# STM32L151xD register map
File version: 1.0
Registers are 32-bit, read-write, reset 0x0 unless marked. A register's access mark holds for its fields unless they carry their own. Offsets are from the block's base; [hi:lo] are bit positions; {n}, {i} and the like mark numbered series; 'fields as' and 'values as' point back to an identical list.

## FSMC_Bank1 — Flexible Static Memory Controller
Base 0xA0000000
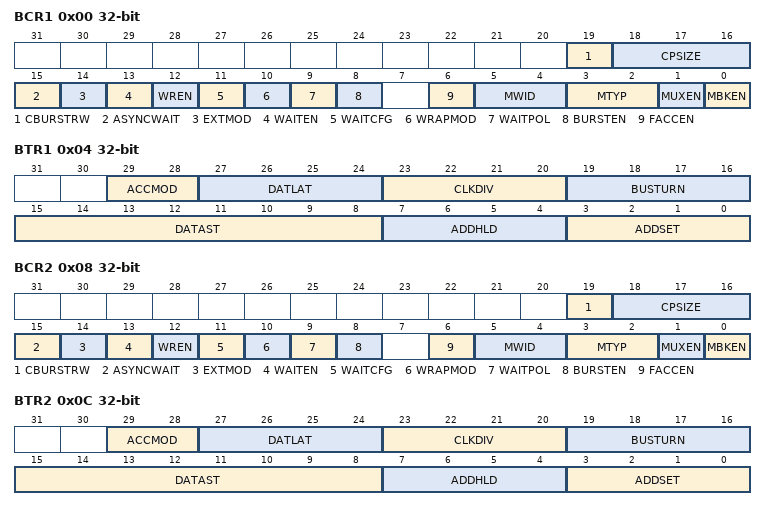
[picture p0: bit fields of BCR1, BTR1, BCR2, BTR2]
0x00 BCR1 — NOR/PSRAM chip-select control register(BCR) and chip-select timing register(BTR)
  [19] CBURSTRW — Write burst enable
  [18:16] CPSIZE — Cellular RAM page size
  [15] ASYNCWAIT — Asynchronous wait
  [14] EXTMOD — Extended mode enable
  [13] WAITEN — Wait enable bit
  [12] WREN — Write enable bit
  [11] WAITCFG — Wait timing configuration
  [10] WRAPMOD — Wrapped burst mode support
  [9] WAITPOL — Wait signal polarity bit
  [8] BURSTEN — Burst enable bit
  [6] FACCEN — Flash access enable
  [5:4] MWID — MWID[1:0] bits (Memory data bus width)
  [3:2] MTYP — MTYP[1:0] bits (Memory type)
  [1] MUXEN — Address/data multiplexing enable bit
  [0] MBKEN — Memory bank enable bit
0x04 BTR1 — NOR/PSRAM chip-select control register(BCR) and chip-select timing register(BTR)
  [29:28] ACCMOD — ACCMOD[1:0] bits (Access mode)
  [27:24] DATLAT — DATLA[3:0] bits (Data latency)
  [23:20] CLKDIV — CLKDIV[3:0] bits (Clock divide ratio)
  [19:16] BUSTURN — BUSTURN[3:0] bits (Bus turnaround phase duration)
  [15:8] DATAST — DATAST [7:0] bits (Data-phase duration)
  [7:4] ADDHLD — ADDHLD[3:0] bits (Address-hold phase duration)
  [3:0] ADDSET — ADDSET[3:0] bits (Address setup phase duration)
0x08 BCR2 — NOR/PSRAM chip-select control register(BCR) and chip-select timing register(BTR)
  fields as BCR1
0x0C BTR2 — NOR/PSRAM chip-select control register(BCR) and chip-select timing register(BTR)
  fields as BTR1
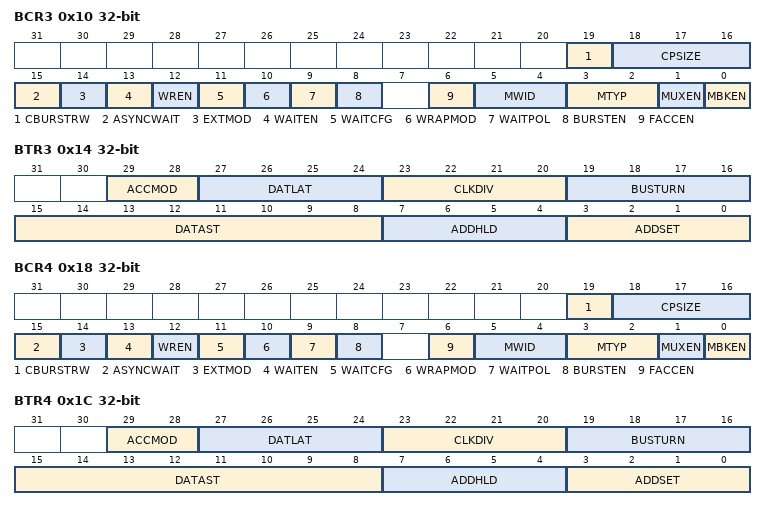
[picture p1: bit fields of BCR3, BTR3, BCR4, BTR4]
0x10 BCR3 — NOR/PSRAM chip-select control register(BCR) and chip-select timing register(BTR)
  fields as BCR1
0x14 BTR3 — NOR/PSRAM chip-select control register(BCR) and chip-select timing register(BTR)
  fields as BTR1
0x18 BCR4 — NOR/PSRAM chip-select control register(BCR) and chip-select timing register(BTR)
  fields as BCR1
0x1C BTR4 — NOR/PSRAM chip-select control register(BCR) and chip-select timing register(BTR)
  fields as BTR1

## FSMC_Bank1E — Flexible Static Memory Controller Bank1E
Base 0xA0000104
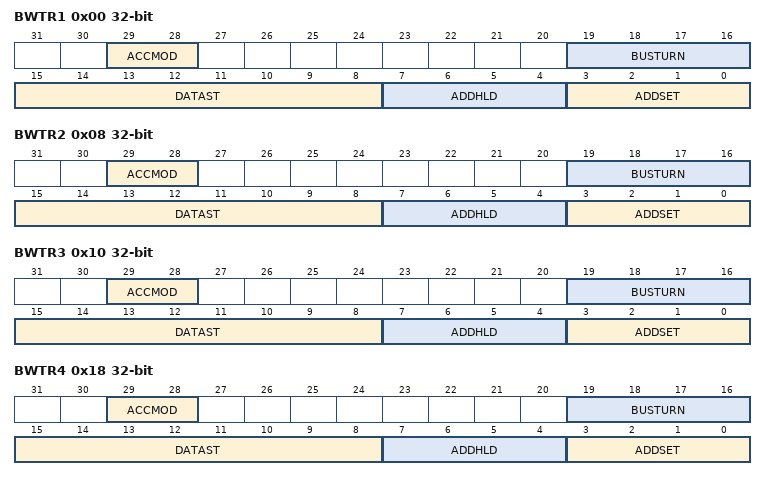
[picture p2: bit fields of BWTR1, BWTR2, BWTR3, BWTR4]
0x00 BWTR1 — NOR/PSRAM write timing registers
  [29:28] ACCMOD — ACCMOD[1:0] bits (Access mode)
  [19:16] BUSTURN — BUSTURN[3:0] bits (Bus turnaround phase duration)
  [15:8] DATAST — DATAST [7:0] bits (Data-phase duration)
  [7:4] ADDHLD — ADDHLD[3:0] bits (Address-hold phase duration)
  [3:0] ADDSET — ADDSET[3:0] bits (Address setup phase duration)
0x08 BWTR2 — NOR/PSRAM write timing registers
  fields as BWTR1
0x10 BWTR3 — NOR/PSRAM write timing registers
  fields as BWTR1
0x18 BWTR4 — NOR/PSRAM write timing registers
  fields as BWTR1

## DBGMCU — Debug MCU
Base 0xE0042000
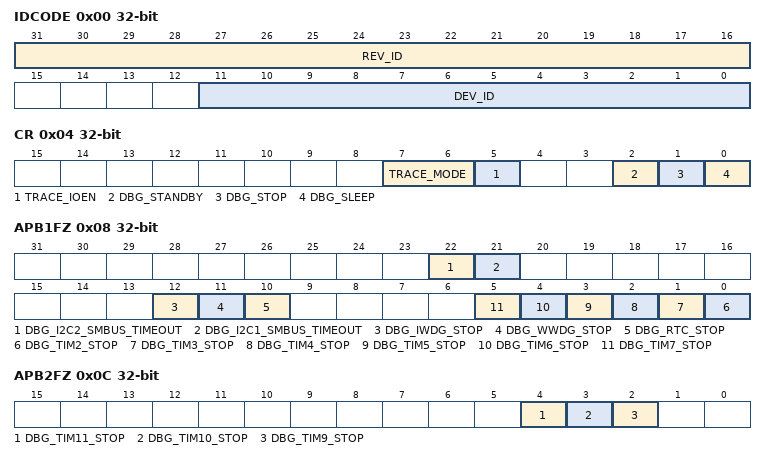
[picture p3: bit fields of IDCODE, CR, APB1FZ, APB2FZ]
0x00 IDCODE — MCU device ID code
  [31:16] REV_ID — REV_ID[15:0] bits (Revision Identifier)
  [11:0] DEV_ID — Device Identifier
0x04 CR — Debug MCU configuration register
  [7:6] TRACE_MODE — TRACE_MODE[1:0] bits (Trace Pin Assignment Control)
  [5] TRACE_IOEN — Trace Pin Assignment Control
  [2] DBG_STANDBY — Debug Standby mode
  [1] DBG_STOP — Debug Stop Mode
  [0] DBG_SLEEP — Debug Sleep Mode
0x08 APB1FZ — Debug MCU APB1 freeze register
  [22] DBG_I2C2_SMBUS_TIMEOUT — SMBUS timeout mode stopped when Core is halted
  [21] DBG_I2C1_SMBUS_TIMEOUT — SMBUS timeout mode stopped when Core is halted
  [12] DBG_IWDG_STOP — Debug Independent Watchdog stopped when Core is halted
  [11] DBG_WWDG_STOP — Debug Window Watchdog stopped when Core is halted
  [10] DBG_RTC_STOP — RTC Counter stopped when Core is halted
  [n-2] DBG_TIM{n}_STOP (n=2..7) — TIM{n} counter stopped when core is halted
0x0C APB2FZ — Debug MCU APB2 freeze register
  [4] DBG_TIM11_STOP — TIM11 counter stopped when core is halted
  [3] DBG_TIM10_STOP — TIM10 counter stopped when core is halted
  [2] DBG_TIM9_STOP — TIM9 counter stopped when core is halted
